# PIC32CZ2038CA70100 device description
Architecture: CORTEX-M7; Family: PIC32CZ; Series: CA70
Registers are 32-bit, read-write, no defined reset value unless marked. A register's access mark holds for its fields unless they carry their own. Offsets are from the block's base; [hi:lo] are bit positions; lines under a group give offsets from that group; {n}, {i} and the like mark numbered series; 'fields as' and 'values as' point back to an identical list; <NAME> marks a mode.

## USBHS — USB High-Speed Interface
Instances: USBHS 0x40038000
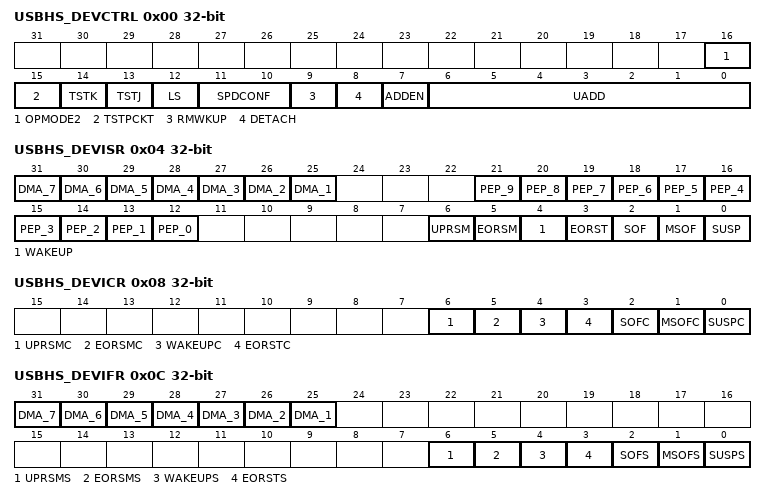
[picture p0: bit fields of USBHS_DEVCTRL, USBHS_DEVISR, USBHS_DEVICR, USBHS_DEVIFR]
0x00 USBHS_DEVCTRL — Device General Control Register
  [16] OPMODE2 — Specific Operational mode
  [15] TSTPCKT — Test packet mode
  [14] TSTK — Test mode K
  [13] TSTJ — Test mode J
  [12] LS — Low-Speed Mode Force
  [11:10] SPDCONF — Mode Configuration
    0=NORMAL (The peripheral starts in Full-speed mode and performs a high-speed reset to switch to High-speed mode if the host is high-speed-capable.); 1=LOW_POWER (For a better consumption, if high speed is not needed.); 2=HIGH_SPEED (Forced high speed.); 3=FORCED_FS (The peripheral remains in Full-speed mode whatever the host speed capability.)
  [9] RMWKUP — Remote Wake-Up
  [8] DETACH
  [7] ADDEN — Address Enable
  [6:0] UADD — USB Address
0x04 USBHS_DEVISR ro — Device Global Interrupt Status Register
  [n+24] DMA_{n} (n=1..7) — DMA Channel {n} Interrupt
  [n+12] PEP_{n} (n=0..9) — Endpoint {n} Interrupt
  [6] UPRSM — Upstream Resume Interrupt
  [5] EORSM — End of Resume Interrupt
  [4] WAKEUP — Wake-Up Interrupt
  [3] EORST — End of Reset Interrupt
  [2] SOF — Start of Frame Interrupt
  [1] MSOF — Micro Start of Frame Interrupt
  [0] SUSP — Suspend Interrupt
0x08 USBHS_DEVICR wo (atomic clear of USBHS_DEVISR) — Device Global Interrupt Clear Register
  [6] UPRSMC — Upstream Resume Interrupt Clear
  [5] EORSMC — End of Resume Interrupt Clear
  [4] WAKEUPC — Wake-Up Interrupt Clear
  [3] EORSTC — End of Reset Interrupt Clear
  [2] SOFC — Start of Frame Interrupt Clear
  [1] MSOFC — Micro Start of Frame Interrupt Clear
  [0] SUSPC — Suspend Interrupt Clear
0x0C USBHS_DEVIFR wo (atomic set of USBHS_DEVISR) — Device Global Interrupt Set Register
  [n+24] DMA_{n} (n=1..7) — DMA Channel {n} Interrupt Set
  [6] UPRSMS — Upstream Resume Interrupt Set
  [5] EORSMS — End of Resume Interrupt Set
  [4] WAKEUPS — Wake-Up Interrupt Set
  [3] EORSTS — End of Reset Interrupt Set
  [2] SOFS — Start of Frame Interrupt Set
  [1] MSOFS — Micro Start of Frame Interrupt Set
  [0] SUSPS — Suspend Interrupt Set
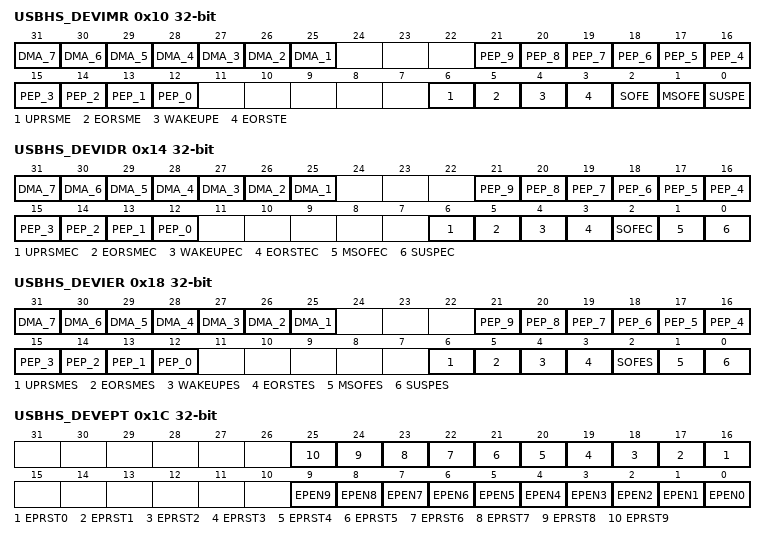
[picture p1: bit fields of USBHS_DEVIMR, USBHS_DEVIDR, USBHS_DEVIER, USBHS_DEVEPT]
0x10 USBHS_DEVIMR ro — Device Global Interrupt Mask Register
  [n+24] DMA_{n} (n=1..7) — DMA Channel {n} Interrupt Mask
  [n+12] PEP_{n} (n=0..9) — Endpoint {n} Interrupt Mask
  [6] UPRSME — Upstream Resume Interrupt Mask
  [5] EORSME — End of Resume Interrupt Mask
  [4] WAKEUPE — Wake-Up Interrupt Mask
  [3] EORSTE — End of Reset Interrupt Mask
  [2] SOFE — Start of Frame Interrupt Mask
  [1] MSOFE — Micro Start of Frame Interrupt Mask
  [0] SUSPE — Suspend Interrupt Mask
0x14 USBHS_DEVIDR wo (atomic clear of USBHS_DEVIMR) — Device Global Interrupt Disable Register
  [n+24] DMA_{n} (n=1..7) — DMA Channel {n} Interrupt Disable
  [n+12] PEP_{n} (n=0..9) — Endpoint {n} Interrupt Disable
  [6] UPRSMEC — Upstream Resume Interrupt Disable
  [5] EORSMEC — End of Resume Interrupt Disable
  [4] WAKEUPEC — Wake-Up Interrupt Disable
  [3] EORSTEC — End of Reset Interrupt Disable
  [2] SOFEC — Start of Frame Interrupt Disable
  [1] MSOFEC — Micro Start of Frame Interrupt Disable
  [0] SUSPEC — Suspend Interrupt Disable
0x18 USBHS_DEVIER wo (atomic set of USBHS_DEVIMR) — Device Global Interrupt Enable Register
  [n+24] DMA_{n} (n=1..7) — DMA Channel {n} Interrupt Enable
  [n+12] PEP_{n} (n=0..9) — Endpoint {n} Interrupt Enable
  [6] UPRSMES — Upstream Resume Interrupt Enable
  [5] EORSMES — End of Resume Interrupt Enable
  [4] WAKEUPES — Wake-Up Interrupt Enable
  [3] EORSTES — End of Reset Interrupt Enable
  [2] SOFES — Start of Frame Interrupt Enable
  [1] MSOFES — Micro Start of Frame Interrupt Enable
  [0] SUSPES — Suspend Interrupt Enable
0x1C USBHS_DEVEPT — Device Endpoint Register
  [n+16] EPRST{n} (n=0..9) — Endpoint {n} Reset
  [n] EPEN{n} (n=0..9) — Endpoint {n} Enable
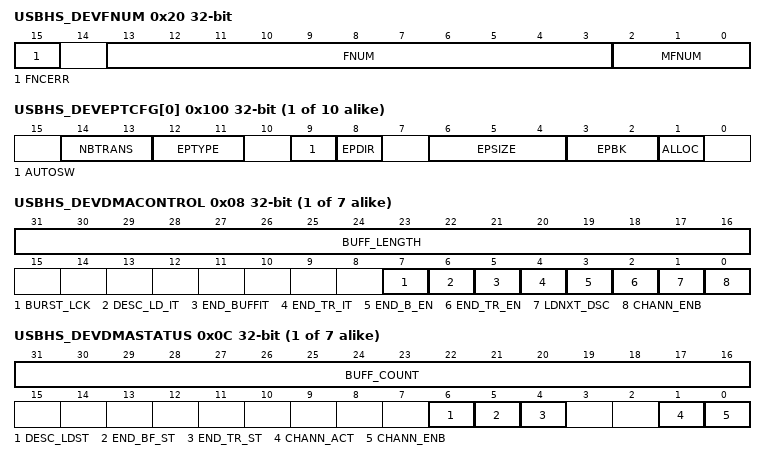
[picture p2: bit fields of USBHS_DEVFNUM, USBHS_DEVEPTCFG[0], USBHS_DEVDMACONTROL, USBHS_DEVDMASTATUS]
0x20 USBHS_DEVFNUM ro — Device Frame Number Register
  [15] FNCERR — Frame Number CRC Error
  [13:3] FNUM — Frame Number
  [2:0] MFNUM — Micro Frame Number
{0x100+4i} USBHS_DEVEPTCFG[{i}] (i=0..9) — Device Endpoint Configuration Register
  [14:13] NBTRANS — Number of transactions per microframe for isochronous endpoint
    0=_0_TRANS (Reserved to endpoint that does not have the high-bandwidth isochronous capability.); 1=_1_TRANS (Default value: one transaction per microframe.); 2=_2_TRANS (Two transactions per microframe. This endpoint should be configured as double-bank.); 3=_3_TRANS (Three transactions per microframe. This endpoint should be configured as triple-bank.)
  [12:11] EPTYPE — Endpoint Type
    0=CTRL (Control); 1=ISO (Isochronous); 2=BLK (Bulk); 3=INTRPT (Interrupt)
  [9] AUTOSW — Automatic Switch
  [8] EPDIR — Endpoint Direction
    0=OUT (The endpoint direction is OUT.); 1=IN (The endpoint direction is IN (nor for control endpoints).)
  [6:4] EPSIZE — Endpoint Size
    0=_8_BYTE (8 bytes); 1=_16_BYTE (16 bytes); 2=_32_BYTE (32 bytes); 3=_64_BYTE (64 bytes); 4=_128_BYTE (128 bytes); 5=_256_BYTE (256 bytes); 6=_512_BYTE (512 bytes); 7=_1024_BYTE (1024 bytes)
  [3:2] EPBK — Endpoint Banks
    0=_1_BANK (Single-bank endpoint); 1=_2_BANK (Double-bank endpoint); 2=_3_BANK (Triple-bank endpoint)
  [1] ALLOC — Endpoint Memory Allocate
{0x130+4i} USBHS_DEVEPTISR[{i}] (i=0..9) ro (modes: ISOCHRONOUS when USBHS_DEVEPTCFG.EPTYPE=0x1) — Device Endpoint Status Register
  [30:20] BYCT — Byte Count
  [18] CFGOK — Configuration OK Status
  [16] RWALL — Read/Write Allowed
  [15:14] CURRBK — Current Bank
    0=BANK0 (Current bank is bank0); 1=BANK1 (Current bank is bank1); 2=BANK2 (Current bank is bank2)
  [13:12] NBUSYBK — Number of Busy Banks
    0=_0_BUSY (0 busy bank (all banks free)); 1=_1_BUSY (1 busy bank); 2=_2_BUSY (2 busy banks); 3=_3_BUSY (3 busy banks)
  [9:8] DTSEQ — Data Toggle Sequence
    0=DATA0 (Data0 toggle sequence); 1=DATA1 (Data1 toggle sequence); 2=DATA2 (Reserved for high-bandwidth isochronous endpoint); 3=MDATA (Reserved for high-bandwidth isochronous endpoint)
  [7] SHORTPACKET — Short Packet Interrupt
  [6] STALLEDI — STALLed Interrupt
  [5] OVERFI — Overflow Interrupt
  [4] NAKINI — NAKed IN Interrupt
  [3] NAKOUTI — NAKed OUT Interrupt
  [2] RXSTPI — Received SETUP Interrupt
  [1] RXOUTI — Received OUT Data Interrupt
  [0] TXINI — Transmitted IN Data Interrupt
  [17] CTRLDIR <CTRL_BULK_INT> — Control Direction
  [10] ERRORTRANS <ISOCHRONOUS> — High-bandwidth Isochronous OUT Endpoint Transaction Error Interrupt
  [6] CRCERRI <ISOCHRONOUS> — CRC Error Interrupt
  [4] HBISOFLUSHI <ISOCHRONOUS> — High Bandwidth Isochronous IN Flush Interrupt
  [3] HBISOINERRI <ISOCHRONOUS> — High Bandwidth Isochronous IN Underflow Error Interrupt
  [2] UNDERFI <ISOCHRONOUS> — Underflow Interrupt
{0x160+4i} USBHS_DEVEPTICR[{i}] (i=0..9) wo (atomic clear of USBHS_DEVEPTISR) (modes: ISOCHRONOUS when USBHS_DEVEPTCFG.EPTYPE=0x1) — Device Endpoint Clear Register
  [7] SHORTPACKETC — Short Packet Interrupt Clear
  [6] STALLEDIC — STALLed Interrupt Clear
  [5] OVERFIC — Overflow Interrupt Clear
  [4] NAKINIC — NAKed IN Interrupt Clear
  [3] NAKOUTIC — NAKed OUT Interrupt Clear
  [2] RXSTPIC — Received SETUP Interrupt Clear
  [1] RXOUTIC — Received OUT Data Interrupt Clear
  [0] TXINIC — Transmitted IN Data Interrupt Clear
  [6] CRCERRIC <ISOCHRONOUS> — CRC Error Interrupt Clear
  [4] HBISOFLUSHIC <ISOCHRONOUS> — High Bandwidth Isochronous IN Flush Interrupt Clear
  [3] HBISOINERRIC <ISOCHRONOUS> — High Bandwidth Isochronous IN Underflow Error Interrupt Clear
  [2] UNDERFIC <ISOCHRONOUS> — Underflow Interrupt Clear
{0x190+4i} USBHS_DEVEPTIFR[{i}] (i=0..9) wo (atomic set of USBHS_DEVEPTISR) (modes: ISOCHRONOUS when USBHS_DEVEPTCFG.EPTYPE=0x1) — Device Endpoint Set Register
  [12] NBUSYBKS — Number of Busy Banks Interrupt Set
  [7] SHORTPACKETS — Short Packet Interrupt Set
  [6] STALLEDIS — STALLed Interrupt Set
  [5] OVERFIS — Overflow Interrupt Set
  [4] NAKINIS — NAKed IN Interrupt Set
  [3] NAKOUTIS — NAKed OUT Interrupt Set
  [2] RXSTPIS — Received SETUP Interrupt Set
  [1] RXOUTIS — Received OUT Data Interrupt Set
  [0] TXINIS — Transmitted IN Data Interrupt Set
  [6] CRCERRIS <ISOCHRONOUS> — CRC Error Interrupt Set
  [4] HBISOFLUSHIS <ISOCHRONOUS> — High Bandwidth Isochronous IN Flush Interrupt Set
  [3] HBISOINERRIS <ISOCHRONOUS> — High Bandwidth Isochronous IN Underflow Error Interrupt Set
  [2] UNDERFIS <ISOCHRONOUS> — Underflow Interrupt Set
{0x1C0+4i} USBHS_DEVEPTIMR[{i}] (i=0..9) ro (modes: ISOCHRONOUS when USBHS_DEVEPTCFG.EPTYPE=0x1) — Device Endpoint Mask Register
  [18] RSTDT — Reset Data Toggle
  [16] EPDISHDMA — Endpoint Interrupts Disable HDMA Request
  [14] FIFOCON — FIFO Control
  [13] KILLBK — Kill IN Bank
  [12] NBUSYBKE — Number of Busy Banks Interrupt
  [7] SHORTPACKETE — Short Packet Interrupt
  [6] STALLEDE — STALLed Interrupt
  [5] OVERFE — Overflow Interrupt
  [4] NAKINE — NAKed IN Interrupt
  [3] NAKOUTE — NAKed OUT Interrupt
  [2] RXSTPE — Received SETUP Interrupt
  [1] RXOUTE — Received OUT Data Interrupt
  [0] TXINE — Transmitted IN Data Interrupt
  [19] STALLRQ <CTRL_BULK_INT> — STALL Request
  [17] NYETDIS <CTRL_BULK_INT> — NYET Token Disable
  [10] ERRORTRANSE <ISOCHRONOUS> — Transaction Error Interrupt
  [9] DATAXE <ISOCHRONOUS> — DataX Interrupt
  [8] MDATAE <ISOCHRONOUS> — MData Interrupt
  [6] CRCERRE <ISOCHRONOUS> — CRC Error Interrupt
  [4] HBISOFLUSHE <ISOCHRONOUS> — High Bandwidth Isochronous IN Flush Interrupt
  [3] HBISOINERRE <ISOCHRONOUS> — High Bandwidth Isochronous IN Underflow Error Interrupt
  [2] UNDERFE <ISOCHRONOUS> — Underflow Interrupt
{0x1F0+4i} USBHS_DEVEPTIER[{i}] (i=0..9) wo (atomic set of USBHS_DEVEPTIMR) (modes: ISOCHRONOUS when USBHS_DEVEPTCFG.EPTYPE=0x1) — Device Endpoint Enable Register
  [18] RSTDTS — Reset Data Toggle Enable
  [16] EPDISHDMAS — Endpoint Interrupts Disable HDMA Request Enable
  [14] FIFOCONS — FIFO Control
  [13] KILLBKS — Kill IN Bank
  [12] NBUSYBKES — Number of Busy Banks Interrupt Enable
  [7] SHORTPACKETES — Short Packet Interrupt Enable
  [6] STALLEDES — STALLed Interrupt Enable
  [5] OVERFES — Overflow Interrupt Enable
  [4] NAKINES — NAKed IN Interrupt Enable
  [3] NAKOUTES — NAKed OUT Interrupt Enable
  [2] RXSTPES — Received SETUP Interrupt Enable
  [1] RXOUTES — Received OUT Data Interrupt Enable
  [0] TXINES — Transmitted IN Data Interrupt Enable
  [19] STALLRQS <CTRL_BULK_INT> — STALL Request Enable
  [17] NYETDISS <CTRL_BULK_INT> — NYET Token Disable Enable
  [10] ERRORTRANSES <ISOCHRONOUS> — Transaction Error Interrupt Enable
  [9] DATAXES <ISOCHRONOUS> — DataX Interrupt Enable
  [8] MDATAES <ISOCHRONOUS> — MData Interrupt Enable
  [6] CRCERRES <ISOCHRONOUS> — CRC Error Interrupt Enable
  [4] HBISOFLUSHES <ISOCHRONOUS> — High Bandwidth Isochronous IN Flush Interrupt Enable
  [3] HBISOINERRES <ISOCHRONOUS> — High Bandwidth Isochronous IN Underflow Error Interrupt Enable
  [2] UNDERFES <ISOCHRONOUS> — Underflow Interrupt Enable
{0x220+4i} USBHS_DEVEPTIDR[{i}] (i=0..9) wo (atomic clear of USBHS_DEVEPTIMR) (modes: ISOCHRONOUS when USBHS_DEVEPTCFG.EPTYPE=0x1) — Device Endpoint Disable Register
  [16] EPDISHDMAC — Endpoint Interrupts Disable HDMA Request Clear
  [14] FIFOCONC — FIFO Control Clear
  [12] NBUSYBKEC — Number of Busy Banks Interrupt Clear
  [7] SHORTPACKETEC — Shortpacket Interrupt Clear
  [6] STALLEDEC — STALLed Interrupt Clear
  [5] OVERFEC — Overflow Interrupt Clear
  [4] NAKINEC — NAKed IN Interrupt Clear
  [3] NAKOUTEC — NAKed OUT Interrupt Clear
  [2] RXSTPEC — Received SETUP Interrupt Clear
  [1] RXOUTEC — Received OUT Data Interrupt Clear
  [0] TXINEC — Transmitted IN Interrupt Clear
  [19] STALLRQC <CTRL_BULK_INT> — STALL Request Clear
  [17] NYETDISC <CTRL_BULK_INT> — NYET Token Disable Clear
  [10] ERRORTRANSEC <ISOCHRONOUS> — Transaction Error Interrupt Clear
  [9] DATAXEC <ISOCHRONOUS> — DataX Interrupt Clear
  [8] MDATAEC <ISOCHRONOUS> — MData Interrupt Clear
  [4] HBISOFLUSHEC <ISOCHRONOUS> — High Bandwidth Isochronous IN Flush Interrupt Clear
  [3] HBISOINERREC <ISOCHRONOUS> — High Bandwidth Isochronous IN Underflow Error Interrupt Clear
  [2] UNDERFEC <ISOCHRONOUS> — Underflow Interrupt Clear
{0x310+0x10*i} USBHS_DEVDMA[{i}] (i=0..6) group — Device DMA Channel Next Descriptor Address Register (n = 1)
  0x00 USBHS_DEVDMANXTDSC — Device DMA Channel Next Descriptor Address Register (n = 1)
    [31:0] NXT_DSC_ADD — Next Descriptor Address
  0x04 USBHS_DEVDMAADDRESS — Device DMA Channel Address Register (n = 1)
    [31:0] BUFF_ADD — Buffer Address
  0x08 USBHS_DEVDMACONTROL — Device DMA Channel Control Register (n = 1)
    [31:16] BUFF_LENGTH — Buffer Byte Length (Write-only)
    [7] BURST_LCK — Burst Lock Enable
    [6] DESC_LD_IT — Descriptor Loaded Interrupt Enable
    [5] END_BUFFIT — End of Buffer Interrupt Enable
    [4] END_TR_IT — End of Transfer Interrupt Enable
    [3] END_B_EN — End of Buffer Enable Control
    [2] END_TR_EN — End of Transfer Enable Control (OUT transfers only)
    [1] LDNXT_DSC — Load Next Channel Transfer Descriptor Enable Command
    [0] CHANN_ENB — Channel Enable Command
  0x0C USBHS_DEVDMASTATUS — Device DMA Channel Status Register (n = 1)
    [31:16] BUFF_COUNT — Buffer Byte Count
    [6] DESC_LDST — Descriptor Loaded Status
    [5] END_BF_ST — End of Channel Buffer Status
    [4] END_TR_ST — End of Channel Transfer Status
    [1] CHANN_ACT — Channel Active Status
    [0] CHANN_ENB — Channel Enable Status
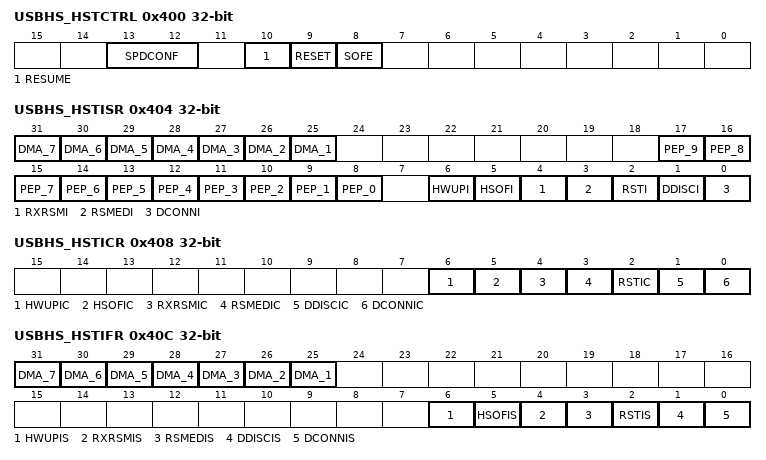
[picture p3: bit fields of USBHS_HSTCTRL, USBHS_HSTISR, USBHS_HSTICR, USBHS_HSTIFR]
0x400 USBHS_HSTCTRL — Host General Control Register
  [13:12] SPDCONF — Mode Configuration
    0=NORMAL (The host starts in Full-speed mode and performs a high-speed reset to switch to High-speed mode if the downstream peripheral is high-speed capable.); 1=LOW_POWER (For a better consumption, if high speed is not needed.); 2=HIGH_SPEED (Forced high speed.); 3=FORCED_FS (The host remains in Full-speed mode whatever the peripheral speed capability.)
  [10] RESUME — Send USB Resume
  [9] RESET — Send USB Reset
  [8] SOFE — Start of Frame Generation Enable
0x404 USBHS_HSTISR ro — Host Global Interrupt Status Register
  [n+24] DMA_{n} (n=1..7) — DMA Channel {n} Interrupt
  [n+8] PEP_{n} (n=0..9) — Pipe {n} Interrupt
  [6] HWUPI — Host Wake-Up Interrupt
  [5] HSOFI — Host Start of Frame Interrupt
  [4] RXRSMI — Upstream Resume Received Interrupt
  [3] RSMEDI — Downstream Resume Sent Interrupt
  [2] RSTI — USB Reset Sent Interrupt
  [1] DDISCI — Device Disconnection Interrupt
  [0] DCONNI — Device Connection Interrupt
0x408 USBHS_HSTICR wo (atomic clear of USBHS_HSTISR) — Host Global Interrupt Clear Register
  [6] HWUPIC — Host Wake-Up Interrupt Clear
  [5] HSOFIC — Host Start of Frame Interrupt Clear
  [4] RXRSMIC — Upstream Resume Received Interrupt Clear
  [3] RSMEDIC — Downstream Resume Sent Interrupt Clear
  [2] RSTIC — USB Reset Sent Interrupt Clear
  [1] DDISCIC — Device Disconnection Interrupt Clear
  [0] DCONNIC — Device Connection Interrupt Clear
0x40C USBHS_HSTIFR wo (atomic set of USBHS_HSTISR) — Host Global Interrupt Set Register
  [n+24] DMA_{n} (n=1..7) — DMA Channel {n} Interrupt Set
  [6] HWUPIS — Host Wake-Up Interrupt Set
  [5] HSOFIS — Host Start of Frame Interrupt Set
  [4] RXRSMIS — Upstream Resume Received Interrupt Set
  [3] RSMEDIS — Downstream Resume Sent Interrupt Set
  [2] RSTIS — USB Reset Sent Interrupt Set
  [1] DDISCIS — Device Disconnection Interrupt Set
  [0] DCONNIS — Device Connection Interrupt Set
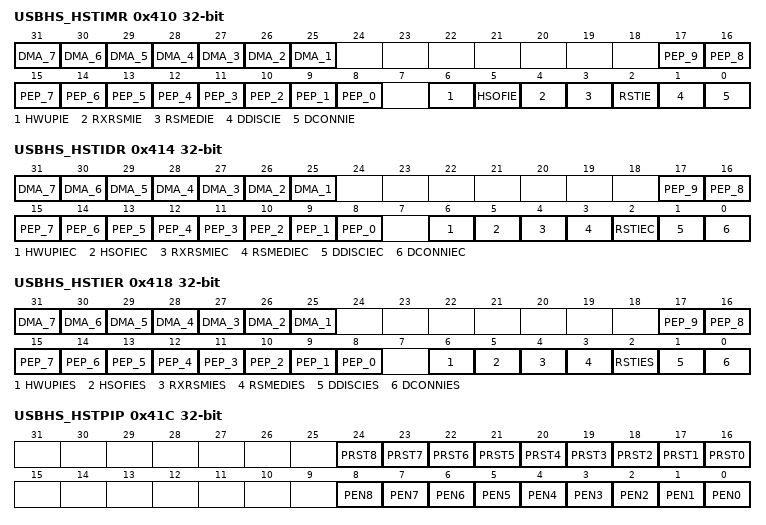
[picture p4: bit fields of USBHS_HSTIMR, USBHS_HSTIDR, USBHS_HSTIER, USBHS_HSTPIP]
0x410 USBHS_HSTIMR ro — Host Global Interrupt Mask Register
  [n+24] DMA_{n} (n=1..7) — DMA Channel {n} Interrupt Enable
  [n+8] PEP_{n} (n=0..9) — Pipe {n} Interrupt Enable
  [6] HWUPIE — Host Wake-Up Interrupt Enable
  [5] HSOFIE — Host Start of Frame Interrupt Enable
  [4] RXRSMIE — Upstream Resume Received Interrupt Enable
  [3] RSMEDIE — Downstream Resume Sent Interrupt Enable
  [2] RSTIE — USB Reset Sent Interrupt Enable
  [1] DDISCIE — Device Disconnection Interrupt Enable
  [0] DCONNIE — Device Connection Interrupt Enable
0x414 USBHS_HSTIDR wo (atomic clear of USBHS_HSTIMR) — Host Global Interrupt Disable Register
  [n+24] DMA_{n} (n=1..7) — DMA Channel {n} Interrupt Disable
  [n+8] PEP_{n} (n=0..9) — Pipe {n} Interrupt Disable
  [6] HWUPIEC — Host Wake-Up Interrupt Disable
  [5] HSOFIEC — Host Start of Frame Interrupt Disable
  [4] RXRSMIEC — Upstream Resume Received Interrupt Disable
  [3] RSMEDIEC — Downstream Resume Sent Interrupt Disable
  [2] RSTIEC — USB Reset Sent Interrupt Disable
  [1] DDISCIEC — Device Disconnection Interrupt Disable
  [0] DCONNIEC — Device Connection Interrupt Disable
0x418 USBHS_HSTIER wo (atomic set of USBHS_HSTIMR) — Host Global Interrupt Enable Register
  [n+24] DMA_{n} (n=1..7) — DMA Channel {n} Interrupt Enable
  [n+8] PEP_{n} (n=0..9) — Pipe {n} Interrupt Enable
  [6] HWUPIES — Host Wake-Up Interrupt Enable
  [5] HSOFIES — Host Start of Frame Interrupt Enable
  [4] RXRSMIES — Upstream Resume Received Interrupt Enable
  [3] RSMEDIES — Downstream Resume Sent Interrupt Enable
  [2] RSTIES — USB Reset Sent Interrupt Enable
  [1] DDISCIES — Device Disconnection Interrupt Enable
  [0] DCONNIES — Device Connection Interrupt Enable
0x41C USBHS_HSTPIP — Host Pipe Register
  [n+16] PRST{n} (n=0..8) — Pipe {n} Reset
  [n] PEN{n} (n=0..8) — Pipe {n} Enable
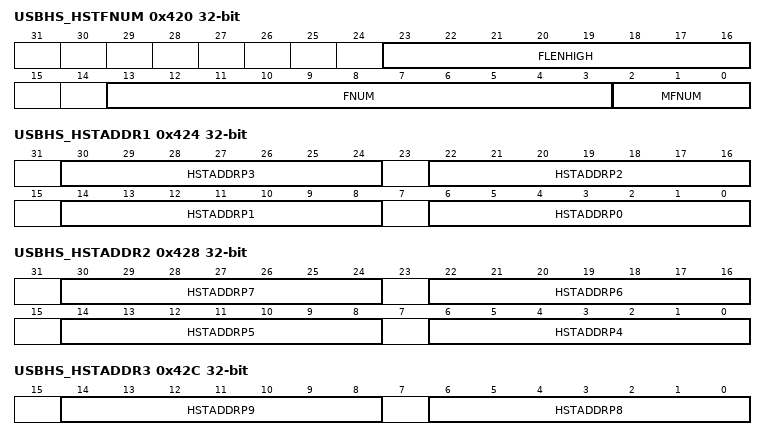
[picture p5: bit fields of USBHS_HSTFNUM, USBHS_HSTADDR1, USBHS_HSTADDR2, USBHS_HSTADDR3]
0x420 USBHS_HSTFNUM — Host Frame Number Register
  [23:16] FLENHIGH — Frame Length
  [13:3] FNUM — Frame Number
  [2:0] MFNUM — Micro Frame Number
0x424 USBHS_HSTADDR1 — Host Address 1 Register
  [8n+6:8n] HSTADDRP{n} (n=0..3) — USB Host Address
0x428 USBHS_HSTADDR2 — Host Address 2 Register
  [8n-26:8n-32] HSTADDRP{n} (n=4..7) — USB Host Address
0x42C USBHS_HSTADDR3 — Host Address 3 Register
  [14:8] HSTADDRP9 — USB Host Address
  [6:0] HSTADDRP8 — USB Host Address
{0x500+4i} USBHS_HSTPIPCFG[{i}] (i=0..9) — Host Pipe Configuration Register
  [31:24] INTFRQ — Pipe Interrupt Request Frequency
  [19:16] PEPNUM — Pipe Endpoint Number
  [13:12] PTYPE — Pipe Type
    values as USBHS_DEVEPTCFG[0].EPTYPE
  [10] AUTOSW — Automatic Switch
  [9:8] PTOKEN — Pipe Token
    0=SETUP; 1=IN; 2=OUT
  [6:4] PSIZE — Pipe Size
    values as USBHS_DEVEPTCFG[0].EPSIZE
  [3:2] PBK — Pipe Banks
    0=_1_BANK (Single-bank pipe); 1=_2_BANK (Double-bank pipe); 2=_3_BANK (Triple-bank pipe)
  [1] ALLOC — Pipe Memory Allocate
  [31:24] BINTERVAL <CTRL_BULK> — bInterval Parameter for the Bulk-Out/Ping Transaction
  [20] PINGEN <CTRL_BULK> — Ping Enable
{0x530+4i} USBHS_HSTPIPISR[{i}] (i=0..9) ro (modes: CTRL_BULK_INT when USBHS_HSTPIPCFG.PTYPE=None; INT_ISO when USBHS_HSTPIPCFG.PTYPE=None; ISOCHRONOUS when USBHS_HSTPIPCFG.PTYPE=0x1) — Host Pipe Status Register
  [30:20] PBYCT — Pipe Byte Count
  [18] CFGOK — Configuration OK Status
  [16] RWALL — Read/Write Allowed
  [15:14] CURRBK — Current Bank
    values as USBHS_DEVEPTISR[0].CURRBK
  [13:12] NBUSYBK — Number of Busy Banks
    values as USBHS_DEVEPTISR[0].NBUSYBK
  [9:8] DTSEQ — Data Toggle Sequence
    0=DATA0 (Data0 toggle sequence); 1=DATA1 (Data1 toggle sequence)
  [7] SHORTPACKETI — Short Packet Interrupt
  [5] OVERFI — Overflow Interrupt
  [4] NAKEDI — NAKed Interrupt
  [3] PERRI — Pipe Error Interrupt
  [2] TXSTPI — Transmitted SETUP Interrupt
  [1] TXOUTI — Transmitted OUT Data Interrupt
  [0] RXINI — Received IN Data Interrupt
  [6] RXSTALLDI <CTRL_BULK_INT> — Received STALLed Interrupt
  [2] UNDERFI <INT_ISO> — Underflow Interrupt
  [6] CRCERRI <ISOCHRONOUS> — CRC Error Interrupt
{0x560+4i} USBHS_HSTPIPICR[{i}] (i=0..9) wo (atomic clear of USBHS_HSTPIPISR) (modes: CTRL_BULK_INT when USBHS_HSTPIPCFG.PTYPE=None; INT_ISO when USBHS_HSTPIPCFG.PTYPE=None; ISOCHRONOUS when USBHS_HSTPIPCFG.PTYPE=0x1) — Host Pipe Clear Register
  [7] SHORTPACKETIC — Short Packet Interrupt Clear
  [5] OVERFIC — Overflow Interrupt Clear
  [4] NAKEDIC — NAKed Interrupt Clear
  [2] TXSTPIC — Transmitted SETUP Interrupt Clear
  [1] TXOUTIC — Transmitted OUT Data Interrupt Clear
  [0] RXINIC — Received IN Data Interrupt Clear
  [6] RXSTALLDIC <CTRL_BULK_INT> — Received STALLed Interrupt Clear
  [2] UNDERFIC <INT_ISO> — Underflow Interrupt Clear
  [6] CRCERRIC <ISOCHRONOUS> — CRC Error Interrupt Clear
{0x590+4i} USBHS_HSTPIPIFR[{i}] (i=0..9) wo (atomic set of USBHS_HSTPIPISR) (modes: CTRL_BULK_INT when USBHS_HSTPIPCFG.PTYPE=None; INT_ISO when USBHS_HSTPIPCFG.PTYPE=None; ISOCHRONOUS when USBHS_HSTPIPCFG.PTYPE=0x1) — Host Pipe Set Register
  [12] NBUSYBKS — Number of Busy Banks Set
  [7] SHORTPACKETIS — Short Packet Interrupt Set
  [5] OVERFIS — Overflow Interrupt Set
  [4] NAKEDIS — NAKed Interrupt Set
  [3] PERRIS — Pipe Error Interrupt Set
  [2] TXSTPIS — Transmitted SETUP Interrupt Set
  [1] TXOUTIS — Transmitted OUT Data Interrupt Set
  [0] RXINIS — Received IN Data Interrupt Set
  [6] RXSTALLDIS <CTRL_BULK_INT> — Received STALLed Interrupt Set
  [2] UNDERFIS <INT_ISO> — Underflow Interrupt Set
  [6] CRCERRIS <ISOCHRONOUS> — CRC Error Interrupt Set
{0x5C0+4i} USBHS_HSTPIPIMR[{i}] (i=0..9) ro (modes: CTRL_BULK_INT when USBHS_HSTPIPCFG.PTYPE=None; INT_ISO when USBHS_HSTPIPCFG.PTYPE=None; ISOCHRONOUS when USBHS_HSTPIPCFG.PTYPE=0x1) — Host Pipe Mask Register
  [18] RSTDT — Reset Data Toggle
  [17] PFREEZE — Pipe Freeze
  [16] PDISHDMA — Pipe Interrupts Disable HDMA Request Enable
  [14] FIFOCON — FIFO Control
  [12] NBUSYBKE — Number of Busy Banks Interrupt Enable
  [7] SHORTPACKETIE — Short Packet Interrupt Enable
  [5] OVERFIE — Overflow Interrupt Enable
  [4] NAKEDE — NAKed Interrupt Enable
  [3] PERRE — Pipe Error Interrupt Enable
  [2] TXSTPE — Transmitted SETUP Interrupt Enable
  [1] TXOUTE — Transmitted OUT Data Interrupt Enable
  [0] RXINE — Received IN Data Interrupt Enable
  [6] RXSTALLDE <CTRL_BULK_INT> — Received STALLed Interrupt Enable
  [2] UNDERFIE <INT_ISO> — Underflow Interrupt Enable
  [6] CRCERRE <ISOCHRONOUS> — CRC Error Interrupt Enable
{0x5F0+4i} USBHS_HSTPIPIER[{i}] (i=0..9) wo (atomic set of USBHS_HSTPIPIMR) (modes: CTRL_BULK_INT when USBHS_HSTPIPCFG.PTYPE=None; INT_ISO when USBHS_HSTPIPCFG.PTYPE=None; ISOCHRONOUS when USBHS_HSTPIPCFG.PTYPE=0x1) — Host Pipe Enable Register
  [18] RSTDTS — Reset Data Toggle Enable
  [17] PFREEZES — Pipe Freeze Enable
  [16] PDISHDMAS — Pipe Interrupts Disable HDMA Request Enable
  [12] NBUSYBKES — Number of Busy Banks Enable
  [7] SHORTPACKETIES — Short Packet Interrupt Enable
  [5] OVERFIES — Overflow Interrupt Enable
  [4] NAKEDES — NAKed Interrupt Enable
  [3] PERRES — Pipe Error Interrupt Enable
  [2] TXSTPES — Transmitted SETUP Interrupt Enable
  [1] TXOUTES — Transmitted OUT Data Interrupt Enable
  [0] RXINES — Received IN Data Interrupt Enable
  [6] RXSTALLDES <CTRL_BULK_INT> — Received STALLed Interrupt Enable
  [2] UNDERFIES <INT_ISO> — Underflow Interrupt Enable
  [6] CRCERRES <ISOCHRONOUS> — CRC Error Interrupt Enable
{0x620+4i} USBHS_HSTPIPIDR[{i}] (i=0..9) wo (atomic clear of USBHS_HSTPIPIMR) (modes: CTRL_BULK_INT when USBHS_HSTPIPCFG.PTYPE=None; INT_ISO when USBHS_HSTPIPCFG.PTYPE=None; ISOCHRONOUS when USBHS_HSTPIPCFG.PTYPE=0x1) — Host Pipe Disable Register
  [17] PFREEZEC — Pipe Freeze Disable
  [16] PDISHDMAC — Pipe Interrupts Disable HDMA Request Disable
  [14] FIFOCONC — FIFO Control Disable
  [12] NBUSYBKEC — Number of Busy Banks Disable
  [7] SHORTPACKETIEC — Short Packet Interrupt Disable
  [5] OVERFIEC — Overflow Interrupt Disable
  [4] NAKEDEC — NAKed Interrupt Disable
  [3] PERREC — Pipe Error Interrupt Disable
  [2] TXSTPEC — Transmitted SETUP Interrupt Disable
  [1] TXOUTEC — Transmitted OUT Data Interrupt Disable
  [0] RXINEC — Received IN Data Interrupt Disable
  [6] RXSTALLDEC <CTRL_BULK_INT> — Received STALLed Interrupt Disable
  [2] UNDERFIEC <INT_ISO> — Underflow Interrupt Disable
  [6] CRCERREC <ISOCHRONOUS> — CRC Error Interrupt Disable
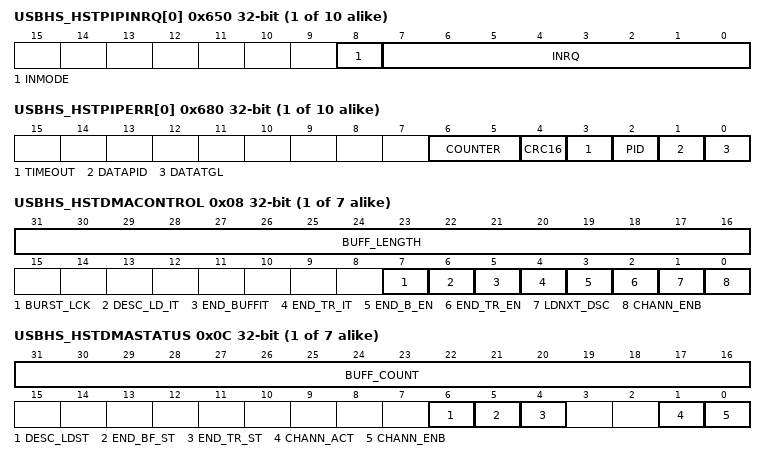
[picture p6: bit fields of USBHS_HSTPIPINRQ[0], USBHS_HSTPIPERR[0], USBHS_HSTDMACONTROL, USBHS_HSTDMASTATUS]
{0x650+4i} USBHS_HSTPIPINRQ[{i}] (i=0..9) — Host Pipe IN Request Register
  [8] INMODE — IN Request Mode
  [7:0] INRQ — IN Request Number before Freeze
{0x680+4i} USBHS_HSTPIPERR[{i}] (i=0..9) — Host Pipe Error Register
  [6:5] COUNTER — Error Counter
  [4] CRC16 — CRC16 Error
  [3] TIMEOUT — Time-Out Error
  [2] PID — Data PID Error
  [1] DATAPID — Data PID Error
  [0] DATATGL — Data Toggle Error
{0x710+0x10*i} USBHS_HSTDMA[{i}] (i=0..6) group — Host DMA Channel Next Descriptor Address Register (n = 1)
  0x00 USBHS_HSTDMANXTDSC — Host DMA Channel Next Descriptor Address Register (n = 1)
    [31:0] NXT_DSC_ADD — Next Descriptor Address
  0x04 USBHS_HSTDMAADDRESS — Host DMA Channel Address Register (n = 1)
    [31:0] BUFF_ADD — Buffer Address
  0x08 USBHS_HSTDMACONTROL — Host DMA Channel Control Register (n = 1)
    fields as USBHS_DEVDMA[0].USBHS_DEVDMACONTROL
  0x0C USBHS_HSTDMASTATUS — Host DMA Channel Status Register (n = 1)
    fields as USBHS_DEVDMA[0].USBHS_DEVDMASTATUS
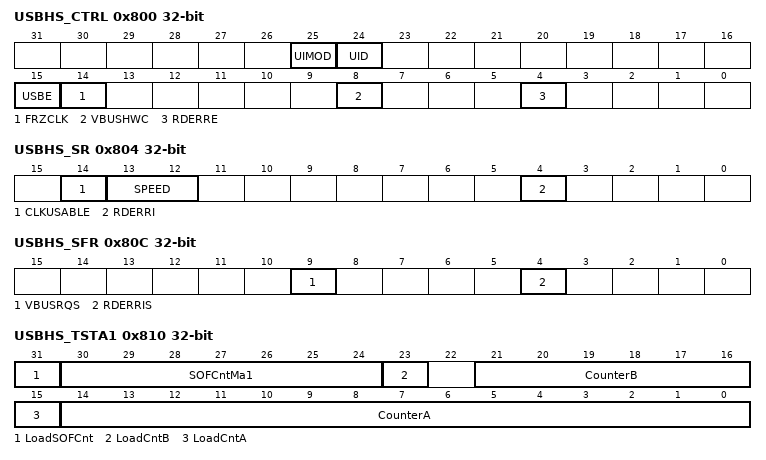
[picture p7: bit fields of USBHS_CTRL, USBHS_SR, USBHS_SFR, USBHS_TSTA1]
0x800 USBHS_CTRL — General Control Register
  [25] UIMOD — USBHS Mode
    0=HOST (The module is in USB Host mode.); 1=DEVICE (The module is in USB Device mode.)
  [24] UID — UID Pin Enable
  [15] USBE — USBHS Enable
  [14] FRZCLK — Freeze USB Clock
  [8] VBUSHWC — VBUS Hardware Control
  [4] RDERRE — Remote Device Connection Error Interrupt Enable
0x804 USBHS_SR ro — General Status Register
  [14] CLKUSABLE — UTMI Clock Usable
  [13:12] SPEED — Speed Status (Device mode only)
    0=FULL_SPEED (Full-Speed mode); 1=HIGH_SPEED (High-Speed mode); 2=LOW_SPEED (Low-Speed mode)
  [4] RDERRI — Remote Device Connection Error Interrupt (Host mode only)
0x808 USBHS_SCR wo (atomic clear of USBHS_SR) — General Status Clear Register
  [4] RDERRIC — Remote Device Connection Error Interrupt Clear
0x80C USBHS_SFR wo (atomic set of USBHS_SR) — General Status Set Register
  [9] VBUSRQS — VBUS Request Set
  [4] RDERRIS — Remote Device Connection Error Interrupt Set
0x810 USBHS_TSTA1 — General Test A1 Register
  [31] LoadSOFCnt — Load SOF Counter
  [30:24] SOFCntMa1 — SOF Counter Max
  [23] LoadCntB — Load CounterB
  [21:16] CounterB
  [15] LoadCntA — Load CounterA
  [14:0] CounterA
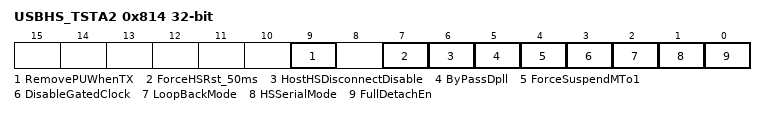
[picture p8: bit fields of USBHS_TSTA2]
0x814 USBHS_TSTA2 — General Test A2 Register
  [9] RemovePUWhenTX — Remove Pull-up When TX
  [7] ForceHSRst_50ms — Force HS Reset to 50 ms
  [6] HostHSDisconnectDisable
  [5] ByPassDpll
  [4] ForceSuspendMTo1
  [3] DisableGatedClock
  [2] LoopBackMode
  [1] HSSerialMode
  [0] FullDetachEn — Full Detach Enable
0x82C USBHS_FSM ro — General Finite State Machine Register
  [3:0] DRDSTATE — Dual Role Device State
    0=A_IDLESTATE (This is the start state for A-devices (when the ID pin is 0)); 1=A_WAIT_VRISE (In this state, the A-device waits for the voltage on VBus to rise above the A-device VBus Valid threshold (4.4 V).); 2=A_WAIT_BCON (In this state, the A-device waits for the B-device to signal a connection.); 3=A_HOST (In this state, the A-device that operates in Host mode is operational.); 4=A_SUSPEND (The A-device operating as a host is in the Suspend mode.); 5=A_PERIPHERAL (The A-device operates as a peripheral.); 6=A_WAIT_VFALL (In this state, the A-device waits for the voltage on VBus to drop below the A-device Session Valid threshold (1.4 V).); 7=A_VBUS_ERR (In this state, the A-device waits for recovery of the over-current condition that caused it to enter this state.); 8=A_WAIT_DISCHARGE (In this state, the A-device waits for the data USB line to discharge (100 us).); 9=B_IDLE (This is the start state for B-device (when the ID pin is 1).); 10=B_PERIPHERAL (In this state, the B-device acts as the peripheral.); 11=B_WAIT_BEGIN_HNP (In this state, the B-device is in Suspend mode and waits until 3 ms before initiating the HNP protocol if requested.); 12=B_WAIT_DISCHARGE (In this state, the B-device waits for the data USB line to discharge (100 us)) before becoming Host.); 13=B_WAIT_ACON (In this state, the B-device waits for the A-device to signal a connect before becoming B-Host.); 14=B_HOST (In this state, the B-device acts as the Host.); 15=B_SRP_INIT (In this state, the B-device attempts to start a session using the SRP protocol.)
